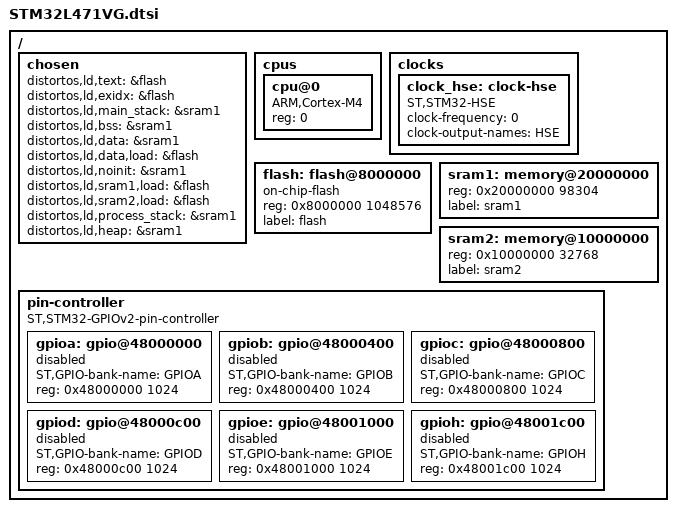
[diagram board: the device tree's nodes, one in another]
/**
 * \file
 * \brief Devicetree fragment for STM32L471VG
 *
 * \author Copyright (C) 2014-2017 Kamil Szczygiel http://www.distortec.com http://www.freddiechopin.info
 *
 * \par License
 * This Source Code Form is subject to the terms of the Mozilla Public License, v. 2.0. If a copy of the MPL was not
 * distributed with this file, You can obtain one at http://mozilla.org/MPL/2.0/.
 *
 * \warning
 * Automatically generated file - do not edit!
 */

#include "ARMv7-M.dtsi"

/ {
	chosen {
		distortos,ld,text = &flash;
		distortos,ld,exidx = &flash;
		distortos,ld,main_stack = &sram1;
		distortos,ld,bss = &sram1;
		distortos,ld,data = &sram1;
		distortos,ld,data,load = &flash;
		distortos,ld,noinit = &sram1;
		distortos,ld,sram1,load = &flash;
		distortos,ld,sram2,load = &flash;
		distortos,ld,process_stack = &sram1;
		distortos,ld,heap = &sram1;
	};

	cpus {
		#address-cells = <1>;
		#size-cells = <0>;

		cpu@0 {
			compatible = "ARM,Cortex-M4", "ARM,ARMv7-M";
			device_type = "cpu";
			reg = <0>;
		};
	};

	clocks {
		clock_hse: clock-hse {
			#clock-cells = <0>;
			compatible = "ST,STM32-HSE", "fixed-clock";
			clock-frequency = <0>;
			clock-output-names = "HSE";
		};
	};

	flash: flash@8000000 {
		compatible = "on-chip-flash";
		reg = <0x8000000 1048576>;
		label = "flash";
	};

	sram1: memory@20000000 {
		device_type = "memory";
		reg = <0x20000000 98304>;
		label = "sram1";
	};

	sram2: memory@10000000 {
		device_type = "memory";
		reg = <0x10000000 32768>;
		label = "sram2";
	};

	pin-controller {
		compatible = "ST,STM32-GPIOv2-pin-controller";
		ranges;
	};

	pin-controller {
		gpioa: gpio@48000000 {
			ST,GPIO-bank-name = "GPIOA";
			#gpio-cells = <2>;
			reg = <0x48000000 1024>;
			status = "disabled";
		};
	};

	pin-controller {
		gpiob: gpio@48000400 {
			ST,GPIO-bank-name = "GPIOB";
			#gpio-cells = <2>;
			reg = <0x48000400 1024>;
			status = "disabled";
		};
	};

	pin-controller {
		gpioc: gpio@48000800 {
			ST,GPIO-bank-name = "GPIOC";
			#gpio-cells = <2>;
			reg = <0x48000800 1024>;
			status = "disabled";
		};
	};

	pin-controller {
		gpiod: gpio@48000c00 {
			ST,GPIO-bank-name = "GPIOD";
			#gpio-cells = <2>;
			reg = <0x48000c00 1024>;
			status = "disabled";
		};
	};

	pin-controller {
		gpioe: gpio@48001000 {
			ST,GPIO-bank-name = "GPIOE";
			#gpio-cells = <2>;
			reg = <0x48001000 1024>;
			status = "disabled";
		};
	};

	pin-controller {
		gpioh: gpio@48001c00 {
			ST,GPIO-bank-name = "GPIOH";
			#gpio-cells = <2>;
			reg = <0x48001c00 1024>;
			status = "disabled";
		};
	};
};
